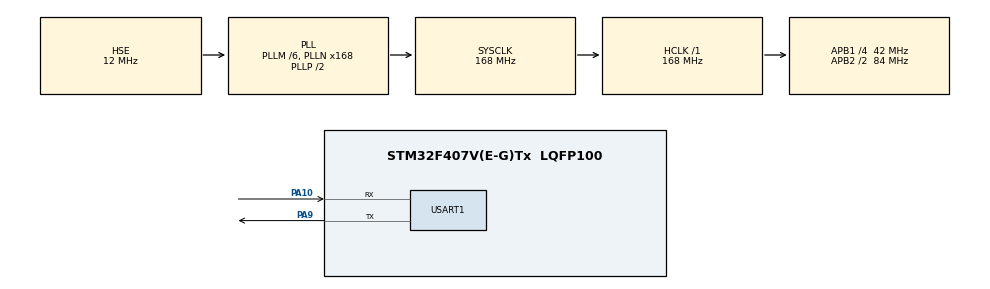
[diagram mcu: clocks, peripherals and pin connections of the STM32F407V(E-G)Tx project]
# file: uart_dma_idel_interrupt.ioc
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Dma.Request0=USART1_RX
Dma.USART1_RX.0.Direction=DMA_PERIPH_TO_MEMORY
Dma.USART1_RX.0.FIFOMode=DMA_FIFOMODE_DISABLE
Dma.USART1_RX.0.Instance=DMA2_Stream2
Dma.USART1_RX.0.MemDataAlignment=DMA_MDATAALIGN_BYTE
Dma.USART1_RX.0.MemInc=DMA_MINC_ENABLE
Dma.USART1_RX.0.Mode=DMA_CIRCULAR
Dma.USART1_RX.0.PeriphDataAlignment=DMA_PDATAALIGN_BYTE
Dma.USART1_RX.0.PeriphInc=DMA_PINC_DISABLE
Dma.USART1_RX.0.Priority=DMA_PRIORITY_LOW
Mcu.Family=STM32F4
Mcu.Name=STM32F407V(E-G)Tx
Mcu.Package=LQFP100
NVIC.DMA2_Stream2_IRQn=true\:0\:0\:false\:false\:true\:false\:true\:true
NVIC.PriorityGroup=NVIC_PRIORITYGROUP_4
NVIC.USART1_IRQn=true\:0\:0\:false\:false\:true\:true\:true\:true
PA10.Mode=Asynchronous
PA10.Signal=USART1_RX
PA13.Mode=Serial_Wire
PA13.Signal=SYS_JTMS-SWDIO
PA14.Mode=Serial_Wire
PA14.Signal=SYS_JTCK-SWCLK
PA9.Mode=Asynchronous
PA9.Signal=USART1_TX
PH0-OSC_IN.Mode=HSE-External-Oscillator
PH0-OSC_IN.Signal=RCC_OSC_IN
PH1-OSC_OUT.Mode=HSE-External-Oscillator
PH1-OSC_OUT.Signal=RCC_OSC_OUT
ProjectManager.HeapSize=0x200
ProjectManager.StackSize=0x400
ProjectManager.TargetToolchain=STM32CubeIDE
RCC.48MHZClocksFreq_Value=84000000
RCC.AHBFreq_Value=168000000
RCC.APB1CLKDivider=RCC_HCLK_DIV4
RCC.APB1Freq_Value=42000000
RCC.APB1TimFreq_Value=84000000
RCC.APB2CLKDivider=RCC_HCLK_DIV2
RCC.APB2Freq_Value=84000000
RCC.APB2TimFreq_Value=168000000
RCC.CortexFreq_Value=168000000
RCC.HCLKFreq_Value=168000000
RCC.HSE_VALUE=12000000
RCC.HSI_VALUE=16000000
RCC.LSE_VALUE=32768
RCC.PLLM=6
RCC.PLLN=168
RCC.PLLSourceVirtual=RCC_PLLSOURCE_HSE
RCC.SYSCLKFreq_VALUE=168000000
RCC.SYSCLKSource=RCC_SYSCLKSOURCE_PLLCLK
RCC.VCOOutputFreq_Value=336000000
USART1.VirtualMode=VM_ASYNC
board=custom

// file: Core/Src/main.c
/* USER CODE BEGIN Header */
/**
  ******************************************************************************
  * @file           : main.c
  * @brief          : Main program body
  ******************************************************************************
  * @attention
  *
  * Copyright (c) 2024 STMicroelectronics.
  * All rights reserved.
  *
  * This software is licensed under terms that can be found in the LICENSE file
  * in the root directory of this software component.
  * If no LICENSE file comes with this software, it is provided AS-IS.
  *
  ******************************************************************************
  */
/* USER CODE END Header */
#include "main.h"
#include "dma.h"
#include "usart.h"
#include "gpio.h"

/* USER CODE BEGIN Includes */
#include "stdarg.h"
#include "stdio.h"
/* USER CODE END Includes */

/* USER CODE BEGIN PD */
#define RX_MAX_LENGTH (500)
/* USER CODE END PD */

/* USER CODE BEGIN PV */
uint8_t receive_buffer_[RX_MAX_LENGTH];
uint32_t rx_count_ = 0;

uint8_t whole_msg_[RX_MAX_LENGTH];
/* USER CODE END PV */

void SystemClock_Config(void);
/* USER CODE BEGIN PFP */
void UartHandle(uint16_t Size);
void ClearRxBuffer();
int uart_printf(char *fmt, ...);
void UartStartDmaRcv();
/* USER CODE END PFP */

int main(void)
{

  /* MCU Configuration--------------------------------------------------------*/

  /* Reset of all peripherals, Initializes the Flash interface and the Systick. */
  HAL_Init();

  /* Configure the system clock */
  SystemClock_Config();

  /* Initialize all configured peripherals */
  MX_GPIO_Init();
  MX_DMA_Init();
  MX_USART1_UART_Init();
  /* USER CODE BEGIN 2 */
  HAL_NVIC_DisableIRQ(DMA2_Stream2_IRQn);

  uart_printf("start uart dma rcv\r\n");
  UartStartDmaRcv();
  /* USER CODE END 2 */

  /* Infinite loop */
  while (1)
  {

  }
}

void SystemClock_Config(void)
{
  RCC_OscInitTypeDef RCC_OscInitStruct = {0};
  RCC_ClkInitTypeDef RCC_ClkInitStruct = {0};

  /** Configure the main internal regulator output voltage
  */
  __HAL_RCC_PWR_CLK_ENABLE();
  __HAL_PWR_VOLTAGESCALING_CONFIG(PWR_REGULATOR_VOLTAGE_SCALE1);

  /** Initializes the RCC Oscillators according to the specified parameters
  * in the RCC_OscInitTypeDef structure.
  */
  RCC_OscInitStruct.OscillatorType = RCC_OSCILLATORTYPE_HSE;
  RCC_OscInitStruct.HSEState = RCC_HSE_ON;
  RCC_OscInitStruct.PLL.PLLState = RCC_PLL_ON;
  RCC_OscInitStruct.PLL.PLLSource = RCC_PLLSOURCE_HSE;
  RCC_OscInitStruct.PLL.PLLM = 6;
  RCC_OscInitStruct.PLL.PLLN = 168;
  RCC_OscInitStruct.PLL.PLLP = RCC_PLLP_DIV2;
  RCC_OscInitStruct.PLL.PLLQ = 4;
  if (HAL_RCC_OscConfig(&RCC_OscInitStruct) != HAL_OK)
  {
    Error_Handler();
  }

  /** Initializes the CPU, AHB and APB buses clocks
  */
  RCC_ClkInitStruct.ClockType = RCC_CLOCKTYPE_HCLK|RCC_CLOCKTYPE_SYSCLK
                              |RCC_CLOCKTYPE_PCLK1|RCC_CLOCKTYPE_PCLK2;
  RCC_ClkInitStruct.SYSCLKSource = RCC_SYSCLKSOURCE_PLLCLK;
  RCC_ClkInitStruct.AHBCLKDivider = RCC_SYSCLK_DIV1;
  RCC_ClkInitStruct.APB1CLKDivider = RCC_HCLK_DIV4;
  RCC_ClkInitStruct.APB2CLKDivider = RCC_HCLK_DIV2;

  if (HAL_RCC_ClockConfig(&RCC_ClkInitStruct, FLASH_LATENCY_5) != HAL_OK)
  {
    Error_Handler();
  }
}

/* USER CODE BEGIN 4 */
void UartStartDmaRcv() {
  HAL_StatusTypeDef ret;
  HAL_UART_DMAStop(&huart1);
  ret = HAL_UARTEx_ReceiveToIdle_DMA(&huart1, receive_buffer_, RX_MAX_LENGTH);
  uart_printf("ret = %d\r\n", ret);
}

/**
  * @brief  Reception Event Callback (Rx event notification called after use of advanced reception service).
  * @param  huart UART handle
  * @param  Size  Number of data available in application reception buffer (indicates a position in
  *               reception buffer until which, data are available)
  * @retval None
  */
void HAL_UARTEx_RxEventCallback(UART_HandleTypeDef *huart, uint16_t Size)
{
  /* Prevent unused argument(s) compilation warning */
  UNUSED(huart);
  UNUSED(Size);

  /* NOTE : This function should not be modified, when the callback is needed,
            the HAL_UARTEx_RxEventCallback can be implemented in the user file.
   */
  if(huart->Instance == USART1)
  {
    UartHandle(Size);
  }
}

void UartHandle(uint16_t Size) {
  uart_printf("receive data length = %d\r\n", Size);
  uart_printf("receive data : ");
  for (rx_count_ = 0; rx_count_ < Size; rx_count_++) {
    whole_msg_[rx_count_] = receive_buffer_[rx_count_];
    uart_printf("%x", receive_buffer_[rx_count_]);
  }
  uart_printf("\r\n");

  ClearRxBuffer();
  UartStartDmaRcv();
}

void ClearRxBuffer()//清空接收缓存
{
  uint32_t i;
  for(i = 0; i < rx_count_; i++)
  {
    receive_buffer_[i] = 0;
  }
  rx_count_ = 0;
}

int uart_printf(char *fmt, ...) {
  char sprint_buf[500];
  va_list args;
  int n;
  va_start(args, fmt);
  n = vsprintf(sprint_buf, fmt, args);
  va_end(args);
  HAL_UART_Transmit(&huart1, (uint8_t *) sprint_buf, n, n);
  return 0;
}
/* USER CODE END 4 */

void Error_Handler(void)
{
  __disable_irq();
  while (1)
  {
  }
}
